# PSC0_FW_0_FW register map
Vendor: Texas Instruments
Peripheral module from a debugger description file (folder am62P).
Registers are 32-bit, read-write, reset 0x0 unless marked. A register's access mark holds for its fields unless they carry their own. Offsets are as the file gives them; lines under a group give offsets from that group; [hi:lo] are bit positions; {n}, {i} and the like mark numbered series; 'fields as' and 'values as' point back to an identical list; <NAME> marks a mode.

## PSC0_FW_0_FW
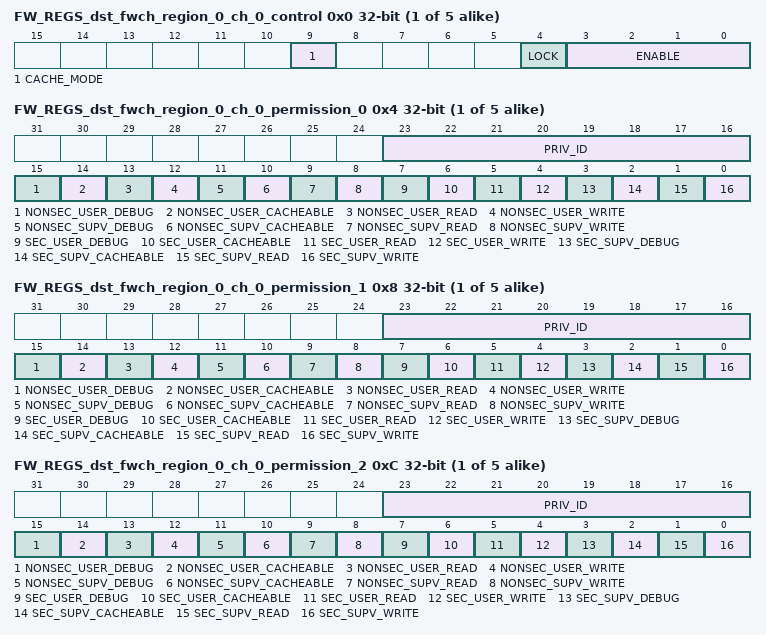
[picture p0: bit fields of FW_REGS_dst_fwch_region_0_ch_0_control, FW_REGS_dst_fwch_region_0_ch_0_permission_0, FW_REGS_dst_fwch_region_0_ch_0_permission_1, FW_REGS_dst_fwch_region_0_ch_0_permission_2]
{0x0+0x20*i} FW_REGS_dst_fwch_region_{i}_ch_0_control access not given (i=0..4) — The FW Region {i} Channel 0 Control Register defines the control fields for the target slv0.slv region {i} channel 0 firewall.
  [9] CACHE_MODE rw — Cache mode for region. Set to 1 to check cache permissions. Set to 0 to ignore cache permissions.
  [4] LOCK — Lock region. Once set region values cannot be modified. (access R/W1TS)
  [3:0] ENABLE rw — Enable region. A value of 0xA enables, others disable.
{0x4+0x20*i} FW_REGS_dst_fwch_region_{i}_ch_0_permission_0 (i=0..4) — The FW Region {i} Channel 0 Permission 0 Register defines the permissions for the target slv0.slv region {i} channel 0 firewall.
  [23:16] PRIV_ID — Allowed privid.
  [15] NONSEC_USER_DEBUG — Non-secure user debug allowed.
  [14] NONSEC_USER_CACHEABLE — Non-secure user cacheable allowed.
  [13] NONSEC_USER_READ — Non-secure user read allowed.
  [12] NONSEC_USER_WRITE — Non-secure user write allowed.
  [11] NONSEC_SUPV_DEBUG — Non-secure supervisor debug allowed.
  [10] NONSEC_SUPV_CACHEABLE — Non-secure supervisor cacheable allowed.
  [9] NONSEC_SUPV_READ — Non-secure supervisor read allowed.
  [8] NONSEC_SUPV_WRITE — Non-secure supervisor write allowed.
  [7] SEC_USER_DEBUG — Secure user debug allowed.
  [6] SEC_USER_CACHEABLE — Secure user cacheable allowed.
  [5] SEC_USER_READ — Secure user read allowed.
  [4] SEC_USER_WRITE — Secure user write allowed.
  [3] SEC_SUPV_DEBUG — Secure supervisor debug allowed.
  [2] SEC_SUPV_CACHEABLE — Secure supervisor cacheable allowed.
  [1] SEC_SUPV_READ — Secure supervisor read allowed.
  [0] SEC_SUPV_WRITE — Secure supervisor write allowed.
{0x8+0x20*i} FW_REGS_dst_fwch_region_{i}_ch_0_permission_1 (i=0..4) — The FW Region {i} Channel 0 Permission 1 Register defines the permissions for the target slv0.slv region {i} channel 0 firewall.
  fields as FW_REGS_dst_fwch_region_0_ch_0_permission_0
{0xC+0x20*i} FW_REGS_dst_fwch_region_{i}_ch_0_permission_2 (i=0..4) — The FW Region {i} Channel 0 Permission 2 Register defines the permissions for the target slv0.slv region {i} channel 0 firewall.
  fields as FW_REGS_dst_fwch_region_0_ch_0_permission_0
